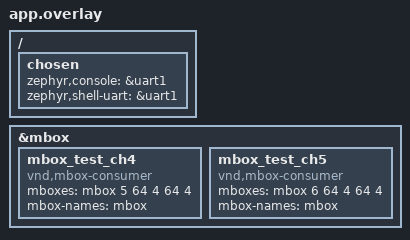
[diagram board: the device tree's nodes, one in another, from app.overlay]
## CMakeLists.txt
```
# SPDX-License-Identifier: Apache-2.0
# mbox_test cpu1 (target) CMakeLists.txt

cmake_minimum_required(VERSION 3.20.0)
find_package(Zephyr REQUIRED HINTS $ENV{ZEPHYR_BASE})
project(cpu1_target_mbox_test)

target_sources(app PRIVATE
    src/main.c
    src/mbox_test_target.c)

target_include_directories(app PRIVATE
    ${CMAKE_CURRENT_SOURCE_DIR}/../tests/include)

include(${CMAKE_CURRENT_SOURCE_DIR}/../../../common/common_sources.cmake)

# 结果上报 + 判定模块（§1.1 修复）：cpu1/cpu2 共用同一份源码
target_sources(app PRIVATE ${CMAKE_CURRENT_SOURCE_DIR}/../tests/src/mbox_test_report.c)

# 扩展 case（P1c 追加）：MBOX_TEST_CASE_ID != 0 时才编入实现文件，
# 保证 case_mbox_basic（ID=0）的构建输入与合并前完全一致。
if(CONFIG_MBOX_TEST_CASE_ID)
    target_sources(app PRIVATE src/mbox_cases.c)
endif()
```

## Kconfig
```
# SPDX-License-Identifier: Apache-2.0
#
# mbox_test cpu1 (target) 应用 Kconfig 根。
# 必须先引入 Zephyr 主配置树，否则整个符号树缺失。

source "$(ZEPHYR_BASE)/Kconfig.zephyr"

# 扩展 case 选择（P1c 追加）。
# 0 = 不编入扩展 case，走原有 mbox_target_main()（case_mbox_basic 原行为）。
config MBOX_TEST_CASE_ID
	int "mbox 扩展 case 编号（0 = 不启用）"
	default 0
	help
	  1 = big_crc   : 4 KB 分片传输 + CRC32 校验
	  2 = stress    : 1000 条往返，丢包/序号/CRC/延迟统计
	  3 = consumers : ch1..ch5 consumer 通路 + 同通道双向
	  4 = invalid   : 异常参数（controller 侧）
	  5 = rtc_sync  : RTC 双核时间同步
	  6 = fifo_full : 屏蔽 IRQ 期 FIFO 满 → -ENOSPC 与补排
```

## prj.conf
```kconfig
CONFIG_LOG=y
CONFIG_LOG_MODE_DEFERRED=y
CONFIG_LOG_BUFFER_SIZE=16384
CONFIG_LOG_PROCESS_THREAD_SLEEP_MS=10
CONFIG_SERIAL=y
CONFIG_SHELL=n
CONFIG_ZTEST=y
CONFIG_ZTEST_ASSERT_VERBOSE=1
CONFIG_ZTEST_VERBOSE_OUTPUT=y
CONFIG_ZTEST_SUMMARY=n
CONFIG_MBOX=y
CONFIG_PICOLIBC=y
CONFIG_NEWLIB_LIBC=n
CONFIG_MINIMAL_LIBC=n
CONFIG_GPIO=y
```

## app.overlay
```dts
/*
 * MBOX test overlay - cpu1 (target) side
 *
 * 新格式（mbox_linkedsemi 驱动改版后）：
 *   mboxes = <&mbox channel tx_width tx_depth rx_width rx_depth>
 *   mbox-names = "mbox"（单一 phandle，不再分 tx/rx）
 *
 * mboxes 首格 = 本节点在 `&mbox` 子节点中的**枚举序**（驱动按遍历序把
 * fifo 填进数组，首格就是数组下标），**以 zephyr.dts 为准**：板级现有 5 个
 * consumer（qspi/otbn/espi/vuart/pcc1 = 0..4），本项目追加 ⇒ 5/6。
 * 节点名 ch4/ch5 为历史命名，实际下标见 mboxes 首格。
 * cpu1 的 tx_fifo_first = <0>（RX fifo first，板级 DTS 已设）。
 */

/ {
	chosen {
		zephyr,console = &uart1;
		zephyr,shell-uart = &uart1;
	};
};

&mbox {
	mbox_test_ch4: mbox_test_ch4 {
		compatible = "vnd,mbox-consumer";
		mboxes = <&mbox 5 64 4 64 4>;
		mbox-names = "mbox";
	};
	mbox_test_ch5: mbox_test_ch5 {
		compatible = "vnd,mbox-consumer";
		mboxes = <&mbox 6 64 4 64 4>;
		mbox-names = "mbox";
	};
};
```

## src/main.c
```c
/*
 * SPDX-License-Identifier: Apache-2.0
 *
 * MBOX test - cpu1 (target) entry point
 * mbox 测试不走 ztest（双核同步复杂），直接跑测试逻辑。
 */

#include <zephyr/kernel.h>
#include <zephyr/logging/log.h>
#include "ztest_glue.h"
#include "mbox_test_report.h"

extern void mbox_target_main(void);
#if defined(CONFIG_MBOX_TEST_CASE_ID) && (CONFIG_MBOX_TEST_CASE_ID > 0)
/* 扩展 case 入口（P1c 追加）：实现见 src/mbox_cases.c，
 * 仅当本目录 Kconfig 的 MBOX_TEST_CASE_ID != 0 时编入。 */
extern void mbox_cases_target_main(void);
#endif

LOG_MODULE_REGISTER(mbox_tgt_main, LOG_LEVEL_INF);

void test_main(void)
{
	LOG_INF("[CPU1 MBOX] MBOX test entry");
	zt_init("TGT");
	mbox_report_init("TGT");

#if defined(CONFIG_MBOX_TEST_CASE_ID) && (CONFIG_MBOX_TEST_CASE_ID > 0)
	mbox_cases_target_main();
#else
	mbox_target_main();
#endif

	/* ★ 按实际判定结果打印 —— 修复前此处**无条件**打 SUCCESSFUL。
	 * 本核的判定状态由 tests/src/mbox_test_report.c 维护（target 侧
	 * 收齐帧数 / payload 校验失败都会置负）。 */
	mbox_print_verdict();

	/* 不返回（§8.1） */
	k_sleep(K_FOREVER);
}
```

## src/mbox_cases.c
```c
/*
 * SPDX-License-Identifier: Apache-2.0
 *
 * MBOX test - cpu1 (target) 扩展 case 实现（P1c 追加）
 *
 * 只实现 V2 协议（mbox_test_protocol.h 追加段）target 侧的应答逻辑；
 * 具体 case 由 CONFIG_MBOX_TEST_CASE_ID 选择（见本目录 Kconfig），
 * 入口 mbox_cases_target_main() 由 src/main.c 在 ID != 0 时调用。
 *
 * 约定：
 *   - ISR 只记账不打 log（§6.1.2），应答统一由本文件的调用线程发送。
 *   - 判定（§1.1/§1.3 修复）：每条 check 用 mbox_item_pass/mbox_item_fail
 *     上报 `INFO <name>: pass=<0|1>,<明细>`，失败置本核判负，src/main.c
 *     在入口返回后按状态打 SUCCESSFUL / FAILED。
 *     修复前失败走 case_fail() 直接打 FAILED，而 main.c 之后仍无条件打
 *     SUCCESSFUL ⇒ 同端口两个互斥标记并存。
 *   - session 判据全在 controller 侧的 case（=4 invalid）用 mbox_item_guard
 *     声明结构性守卫，不得冒充行为证据（§1.4）。
 *   - 驱动的收发 fifo 按通道成对分配于共享 SRAM 的 MBOX 区，同一通道
 *     双向可用，故 echo 类应答走原通道。
 */

#include <zephyr/kernel.h>
#include <zephyr/device.h>
#include <zephyr/devicetree.h>
#include <zephyr/drivers/mbox.h>
#include <zephyr/logging/log.h>
#include <string.h>

#if defined(CONFIG_RTC)
#include <zephyr/drivers/rtc.h>
#endif

#include "mbox_test_protocol.h"
#include "mbox_test_report.h"

LOG_MODULE_REGISTER(mbox_tgt_cases, LOG_LEVEL_INF);

/* consumer 通道 spec。ch0(qspi1) 在本构建中由 flash delegation server
 * 占用（soc_flash_ls.c 注册了回调），扩展 case 不使用该通道。 */
static const struct mbox_dt_spec ch1 = MBOX_DT_SPEC_GET(DT_NODELABEL(mbox_consumer_otbn_crypto), mbox);
static const struct mbox_dt_spec ch2 = MBOX_DT_SPEC_GET(DT_NODELABEL(mbox_consumer_espi1), mbox);
static const struct mbox_dt_spec ch3 = MBOX_DT_SPEC_GET(DT_NODELABEL(mbox_consumer_vuart1), mbox);
static const struct mbox_dt_spec ch4 = MBOX_DT_SPEC_GET(DT_NODELABEL(mbox_test_ch4), mbox);
static const struct mbox_dt_spec ch5 = MBOX_DT_SPEC_GET(DT_NODELABEL(mbox_test_ch5), mbox);

/* 各通道 MTU（= mboxes 的 tx_fifo_width cell，收发同宽） */
#define W_CH1  DT_PHA_BY_IDX(DT_NODELABEL(mbox_consumer_otbn_crypto), mboxes, 0, tx_fifo_width)
#define W_CH2  DT_PHA_BY_IDX(DT_NODELABEL(mbox_consumer_espi1), mboxes, 0, tx_fifo_width)
#define W_CH3  DT_PHA_BY_IDX(DT_NODELABEL(mbox_consumer_vuart1), mboxes, 0, tx_fifo_width)
#define W_CH4  DT_PHA_BY_IDX(DT_NODELABEL(mbox_test_ch4), mboxes, 0, tx_fifo_width)
#define W_CH5  DT_PHA_BY_IDX(DT_NODELABEL(mbox_test_ch5), mboxes, 0, tx_fifo_width)

/* 协议常量必须与板级 dts 一致：FIFO 满 case 的判据依赖 ch4/ch5 深度 */
_Static_assert(MBOX_FIFO_DEPTH ==
	       DT_PHA_BY_IDX(DT_NODELABEL(mbox_test_ch4), mboxes, 0, tx_fifo_depth),
	       "MBOX_FIFO_DEPTH 与 mbox_test_ch4 的 fifo 深度不一致");
_Static_assert(MBOX_TEST_V2_MSG_LEN == W_CH4,
	       "V2 帧长必须等于 ch4 MTU");

/* 暂存槽：驱动侧 rx msg.size 恒为该通道 width，按最大 width（64）开槽 */
#define CASE_RX_SLOT  MBOX_TEST_V2_MSG_LEN

static K_SEM_DEFINE(case_rx_sem, 0, 1);
static uint8_t  case_rx_buf[CASE_RX_SLOT];
static volatile uint32_t case_rx_len;
static volatile uint32_t case_rx_ch;
static volatile uint32_t case_rx_total;
static volatile uint32_t case_rx_drop;

static void case_rx_cb(const struct device *dev, mbox_channel_id_t ch,
		       void *user_data, struct mbox_msg *msg)
{
	/* ISR：只记账 */
	case_rx_total++;
	if (msg == NULL || msg->data == NULL || msg->size > sizeof(case_rx_buf)) {
		case_rx_drop++;
		return;
	}
	memcpy(case_rx_buf, msg->data, msg->size);
	case_rx_len = msg->size;
	case_rx_ch = ch;
	k_sem_give(&case_rx_sem);
}

/* 阻塞等待一条暂存消息；返回 0 = 有消息 */
static int case_wait(uint32_t timeout_ms)
{
	return k_sem_take(&case_rx_sem, K_MSEC(timeout_ms));
}

static void case_take(struct mbox_test_msg_v2 *m)
{
	memset(m, 0, sizeof(*m));
	memcpy(m, case_rx_buf, MIN(case_rx_len, sizeof(*m)));
}

/* 本帧中实际存在的载荷字节数（短通道帧尾部无载荷） */
static uint32_t case_payload_len(void)
{
	return (case_rx_len > MBOX_TEST_V2_HDR_LEN) ?
	       MIN(case_rx_len - MBOX_TEST_V2_HDR_LEN, (uint32_t)MBOX_TEST_V2_DATA_LEN) : 0u;
}

static int case_send(const struct mbox_dt_spec *spec, struct mbox_test_msg_v2 *m, uint32_t size)
{
	struct mbox_msg msg = { .data = m, .size = size };

	return mbox_send_dt(spec, &msg);
}

static void case_setup(const struct mbox_dt_spec *spec)
{
	(void)mbox_register_callback(spec->dev, spec->channel_id, case_rx_cb, NULL);
	(void)mbox_set_enabled(spec->dev, spec->channel_id, true);
}

/* ------------------------------------------------------------------ */
/* case 1：4 KB 分片传输 + CRC32                                        */
/* ------------------------------------------------------------------ */
static void case_big_crc(void)
{
	static uint8_t big[MBOX_BIG_CRC_TOTAL];
	struct mbox_test_msg_v2 m;
	uint32_t got = 0, pattern_err = 0, seq_err = 0, ack_err = 0;
	uint32_t crc_tgt, crc_peer = 0, verdict = MBOX_V2_ST_OK;

	case_setup(&ch4);

	LOG_INF("[TGT] big_crc: expect %u B in %u chunks",
		(unsigned)MBOX_BIG_CRC_TOTAL, (unsigned)MBOX_BIG_CRC_CHUNKS);

	for (;;) {
		if (case_wait(20000) != 0) {
			verdict = MBOX_V2_ST_TIMEOUT;
			break;
		}
		case_take(&m);
		if (m.magic != MBOX_TEST_MAGIC_V2) {
			pattern_err++;
			continue;
		}
		if (m.op == MBOX_V2_OP_DATA) {
			uint32_t off = m.seq * MBOX_TEST_V2_DATA_LEN;
			uint32_t n;
			struct mbox_test_msg_v2 ack;

			if (off >= MBOX_BIG_CRC_TOTAL) {
				seq_err++;
				continue;
			}
			n = MIN((uint32_t)MBOX_TEST_V2_DATA_LEN,
				(uint32_t)MBOX_BIG_CRC_TOTAL - off);
			memcpy(&big[off], m.payload, n);
			for (uint32_t i = 0; i < n; i++) {
				if (big[off + i] != MBOX_BIG_CRC_PATTERN(off + i)) {
					pattern_err++;
				}
			}
			got += n;

			ack.magic = MBOX_TEST_MAGIC_V2;
			ack.op = MBOX_V2_OP_ACK;
			ack.status = (uint8_t)pattern_err;
			ack.seq = m.seq;
			ack.aux = got;
			memset(ack.payload, 0, sizeof(ack.payload));
			if (case_send(&ch5, &ack, W_CH5) != 0) {
				ack_err++;
			}
		} else if (m.op == MBOX_V2_OP_DONE) {
			crc_peer = m.aux;
			break;
		} else {
			pattern_err++;
		}
	}

	crc_tgt = mbox_test_crc32(big, MBOX_BIG_CRC_TOTAL, 0);
	if (got != MBOX_BIG_CRC_TOTAL) {
		verdict = MBOX_V2_ST_SEQ;
	} else if (pattern_err != 0) {
		verdict = MBOX_V2_ST_PATTERN;
	} else if (crc_tgt != crc_peer) {
		verdict = MBOX_V2_ST_CRC;
	}

	/* 汇总上报：aux = 本地 CRC32，payload 前 12 字节 = 接收量/错量 */
	struct mbox_test_msg_v2 stat = {
		.magic = MBOX_TEST_MAGIC_V2,
		.op = MBOX_V2_OP_STAT,
		.status = (uint8_t)verdict,
		.seq = MBOX_BIG_CRC_CHUNKS,
		.aux = crc_tgt,
	};

	memcpy(&stat.payload[0], &got, 4);
	memcpy(&stat.payload[4], &pattern_err, 4);
	memcpy(&stat.payload[8], &ack_err, 4);
	(void)case_send(&ch5, &stat, W_CH5);

	/* ① 端到端完整性：重组字节数 / 逐字节 pattern / 两核 CRC32 */
	if (verdict == MBOX_V2_ST_OK) {
		mbox_item_pass(MBOX_I_BIG_PAYLOAD_CRC, "big_payload_crc",
			       "bytes=%u,recv=%u,pattern_err=%u,seq_err=%u,"
			       "crc=0x%08x,peer_crc=0x%08x",
			       (unsigned)MBOX_BIG_CRC_TOTAL, (unsigned)got,
			       (unsigned)pattern_err, (unsigned)seq_err,
			       (unsigned)crc_tgt, (unsigned)crc_peer);
	} else {
		mbox_item_fail(MBOX_I_BIG_PAYLOAD_CRC, "big_payload_crc",
			       "bytes=%u,recv=%u,pattern_err=%u,seq_err=%u,"
			       "crc=0x%08x,peer_crc=0x%08x,verdict_st=%u",
			       (unsigned)MBOX_BIG_CRC_TOTAL, (unsigned)got,
			       (unsigned)pattern_err, (unsigned)seq_err,
			       (unsigned)crc_tgt, (unsigned)crc_peer,
			       (unsigned)verdict);
	}

	/* ② 逐片 ACK 的回传链路（本核发送侧） */
	if (ack_err == 0 && got == MBOX_BIG_CRC_TOTAL) {
		mbox_item_pass(MBOX_I_BIG_CRC_CHUNK_ACK, "big_crc_chunk_ack",
			       "chunks=%u,ack_err=%u",
			       (unsigned)MBOX_BIG_CRC_CHUNKS, (unsigned)ack_err);
	} else {
		mbox_item_fail(MBOX_I_BIG_CRC_CHUNK_ACK, "big_crc_chunk_ack",
			       "chunks=%u,ack_err=%u,recv=%u",
			       (unsigned)MBOX_BIG_CRC_CHUNKS, (unsigned)ack_err,
			       (unsigned)got);
	}
}

/* ------------------------------------------------------------------ */
/* case 2：1000 条往返，丢包/序号/CRC/延迟统计                          */
/* ------------------------------------------------------------------ */
static void case_stress(void)
{
	struct mbox_test_msg_v2 m;
	uint32_t cnt = 0, seq_err = 0, payload_err = 0, expect = 0;
	uint32_t crc = 0, verdict = MBOX_V2_ST_OK, isr_total, isr_drop;
	bool flow_ok;

	case_setup(&ch4);

	for (;;) {
		if (case_wait(60000) != 0) {
			verdict = MBOX_V2_ST_TIMEOUT;
			break;
		}
		case_take(&m);
		if (m.magic != MBOX_TEST_MAGIC_V2) {
			continue;
		}
		if (m.op == MBOX_V2_OP_DONE) {
			break;
		}
		if (m.op != MBOX_V2_OP_ECHO) {
			continue;
		}

		cnt++;
		if (m.seq != expect) {
			seq_err++;
		}
		expect = m.seq + 1;
		for (uint32_t j = 0; j < MBOX_TEST_V2_DATA_LEN; j++) {
			if (m.payload[j] != (uint8_t)(m.seq + j)) {
				payload_err++;
				break;
			}
		}
		crc = mbox_test_crc32(m.payload, MBOX_TEST_V2_DATA_LEN, crc);

		struct mbox_test_msg_v2 ack = {
			.magic = MBOX_TEST_MAGIC_V2,
			.op = MBOX_V2_OP_ACK,
			.status = (uint8_t)seq_err,
			.seq = m.seq,
			.aux = crc,
		};

		(void)case_send(&ch5, &ack, W_CH5);
	}

	isr_total = case_rx_total;
	isr_drop = case_rx_drop;

	struct mbox_test_msg_v2 stat = {
		.magic = MBOX_TEST_MAGIC_V2,
		.op = MBOX_V2_OP_STAT,
		.status = (uint8_t)((seq_err || payload_err) ? MBOX_V2_ST_SEQ : MBOX_V2_ST_OK),
		.seq = cnt,
		.aux = cnt,
	};

	memcpy(&stat.payload[0], &crc, 4);
	memcpy(&stat.payload[4], &seq_err, 4);
	memcpy(&stat.payload[8], &payload_err, 4);
	memcpy(&stat.payload[12], &isr_total, 4);
	memcpy(&stat.payload[16], &isr_drop, 4);
	(void)case_send(&ch5, &stat, W_CH5);

	flow_ok = (verdict == MBOX_V2_ST_OK) && (seq_err == 0) &&
		  (payload_err == 0) && (isr_drop == 0) &&
		  (cnt == MBOX_STRESS_COUNT);
	if (flow_ok) {
		mbox_item_pass(MBOX_I_STRESS_N_MESSAGES, "stress_n_messages",
			       "recv=%u,expect=%u,seq_err=%u,payload_err=%u,"
			       "isr_total=%u,isr_drop=%u,crc=0x%08x",
			       (unsigned)cnt, (unsigned)MBOX_STRESS_COUNT,
			       (unsigned)seq_err, (unsigned)payload_err,
			       (unsigned)isr_total, (unsigned)isr_drop,
			       (unsigned)crc);
	} else {
		mbox_item_fail(MBOX_I_STRESS_N_MESSAGES, "stress_n_messages",
			       "recv=%u,expect=%u,seq_err=%u,payload_err=%u,"
			       "isr_total=%u,isr_drop=%u,crc=0x%08x,verdict_st=%u",
			       (unsigned)cnt, (unsigned)MBOX_STRESS_COUNT,
			       (unsigned)seq_err, (unsigned)payload_err,
			       (unsigned)isr_total, (unsigned)isr_drop,
			       (unsigned)crc, (unsigned)verdict);
	}
}

/* ------------------------------------------------------------------ */
/* case 3：consumer 通道通路（ch1..ch5；ch0 归 flash delegation）        */
/* ------------------------------------------------------------------ */
static const struct mbox_dt_spec *probe_ch[] = { &ch1, &ch2, &ch3, &ch4 };
static const uint32_t probe_w[] = { W_CH1, W_CH2, W_CH3, W_CH4 };
static const char *probe_name[] = {
	"consumer_ch1_roundtrip", "consumer_ch2_roundtrip",
	"consumer_ch3_roundtrip", "consumer_ch4_roundtrip"
};
static const enum mbox_item probe_item[] = {
	MBOX_I_CONSUMER_CH1, MBOX_I_CONSUMER_CH2, MBOX_I_CONSUMER_CH3, MBOX_I_CONSUMER_CH4
};
#define PROBE_N ARRAY_SIZE(probe_ch)

static void case_consumers(void)
{
	struct mbox_test_msg_v2 m;
	uint32_t ok = 0, bad = 0;
	uint32_t short_frame_len = 0;
	bool probe_ok[PROBE_N];
	bool short_ok;

	for (uint32_t i = 0; i < PROBE_N; i++) {
		case_setup(probe_ch[i]);
		probe_ok[i] = false;
	}
	case_setup(&ch5);

	for (uint32_t i = 0; i < PROBE_N; i++) {
		struct mbox_test_msg_v2 ack;
		bool this_ok = false;
		bool payload_ok = true;

		if (case_wait(5000) != 0) {
			continue;
		}
		case_take(&m);
		if (m.magic == MBOX_TEST_MAGIC_V2 && m.op == MBOX_V2_OP_ECHO &&
		    m.seq == i && case_rx_ch == probe_ch[i]->channel_id &&
		    case_rx_len == probe_w[i]) {
			/* 载荷区只在通道 width > V2 头部长度时存在 */
			for (uint32_t j = 0; j < case_payload_len(); j++) {
				if (m.payload[j] != (uint8_t)(0xA0 + i)) {
					payload_ok = false;
					break;
				}
			}
			this_ok = payload_ok;
		}

		ack.magic = MBOX_TEST_MAGIC_V2;
		ack.op = MBOX_V2_OP_ACK;
		ack.status = this_ok ? MBOX_V2_ST_OK : MBOX_V2_ST_ARG;
		ack.seq = i;
		ack.aux = case_rx_ch;
		memset(ack.payload, 0, sizeof(ack.payload));
		if (case_send(probe_ch[i], &ack, probe_w[i]) == 0 && this_ok) {
			probe_ok[i] = true;
			ok++;
		} else {
			bad++;
		}
	}

	/* ch5 短帧：controller 只发 8 B，驱动 rx size 恒报通道 width(64) */
	if (case_wait(5000) == 0) {
		struct mbox_test_msg_v2 ack;

		case_take(&m);
		short_frame_len = case_rx_len;
		short_ok = (m.op == MBOX_V2_OP_ECHO) && (case_rx_len == W_CH5);
		ack.magic = MBOX_TEST_MAGIC_V2;
		ack.op = MBOX_V2_OP_ACK;
		ack.status = short_ok ? MBOX_V2_ST_OK : MBOX_V2_ST_ARG;
		ack.seq = m.seq;
		ack.aux = case_rx_len;
		memset(ack.payload, 0, sizeof(ack.payload));
		(void)case_send(&ch5, &ack, W_CH5);
	} else {
		short_ok = false;
		bad++;
	}

	/* ① 每个 consumer 通道各自一项 */
	for (uint32_t i = 0; i < PROBE_N; i++) {
		if (probe_ok[i]) {
			mbox_item_pass(probe_item[i], probe_name[i],
				       "ch=%u,size=%u",
				       (unsigned)probe_ch[i]->channel_id,
				       (unsigned)probe_w[i]);
		} else {
			mbox_item_fail(probe_item[i], probe_name[i],
				       "ch=%u,size=%u",
				       (unsigned)probe_ch[i]->channel_id,
				       (unsigned)probe_w[i]);
		}
	}

	/* ② 同一通道双向：ACK 必须由收到的原通道发回（本核 TX/RX region 对偶） */
	if (ok == PROBE_N && bad == 0) {
		mbox_item_pass(MBOX_I_CONSUMER_BIDIR, "consumer_same_channel_bidir",
			       "bidir_ok=%u/%u", (unsigned)ok, (unsigned)PROBE_N);
	} else {
		mbox_item_fail(MBOX_I_CONSUMER_BIDIR, "consumer_same_channel_bidir",
			       "bidir_ok=%u/%u,bad=%u", (unsigned)ok,
			       (unsigned)PROBE_N, (unsigned)bad);
	}

	/* ③ ch5 短帧契约：对端发 8 B，本端 rx size 仍报通道 width(64) */
	if (short_ok) {
		mbox_item_pass(MBOX_I_CONSUMER_CH5_SHORT, "consumer_ch5_short_frame",
			       "rx_len=%u,expect=%u",
			       (unsigned)short_frame_len, (unsigned)W_CH5);
	} else {
		mbox_item_fail(MBOX_I_CONSUMER_CH5_SHORT, "consumer_ch5_short_frame",
			       "rx_len=%u,expect=%u",
			       (unsigned)short_frame_len, (unsigned)W_CH5);
	}
}

/* ------------------------------------------------------------------ */
/* case 4：异常参数（判据在 controller 侧，target 仅待机）               */
/* ------------------------------------------------------------------ */
static void case_invalid(void)
{
	/* 本 case 的判据（非法入参返回值）全部在 controller 侧，target 侧
	 * 没有可校验的行为 —— 用 guard 显式声明"本项不是行为证据"，避免它
	 * 继续冒充"双核行为验证"的一半（§1.4）。 */
	LOG_INF("[TGT] invalid: 判据在 controller 侧，target 待机");
	k_msleep(4000);
	mbox_item_guard(MBOX_I_STRUCT_GUARD, "tgt_invalid_idle", "idle_ms=4000");
}

/* ------------------------------------------------------------------ */
/* case 5：RTC 双核时间同步                                            */
/* ------------------------------------------------------------------ */
static void case_rtc_sync(void)
{
#if defined(CONFIG_RTC)
	const struct device *rtc = DEVICE_DT_GET(DT_NODELABEL(rtc));
	struct rtc_time tm;
	struct mbox_test_msg_v2 m, ack;
	uint32_t e1 = 0, e2 = 0;
	int32_t advance = -1;
	uint32_t bad = 0;

	case_setup(&ch4);

	if (!device_is_ready(rtc)) {
		mbox_mark_fail("rtc device not ready");
		return;
	}

	/* 第 1 轮：应答 controller 的时间戳请求 */
	if (case_wait(20000) != 0) {
		mbox_mark_fail("rtc sync round1 超时");
		return;
	}
	case_take(&m);
	if (rtc_get_time(rtc, &tm) != 0) {
		bad++;
	} else {
		e1 = mbox_test_epoch(tm.tm_year + 1900, tm.tm_mon, tm.tm_mday,
				     tm.tm_hour, tm.tm_min, tm.tm_sec);
	}

	/* 走时推进：隔 300 ms 再读一次，本地 RTC 应前进 0..3 s */
	k_msleep(300);
	if (rtc_get_time(rtc, &tm) != 0) {
		bad++;
	} else {
		e2 = mbox_test_epoch(tm.tm_year + 1900, tm.tm_mon, tm.tm_mday,
				     tm.tm_hour, tm.tm_min, tm.tm_sec);
		advance = (int32_t)e2 - (int32_t)e1;
	}

	memset(&ack, 0, sizeof(ack));
	ack.magic = MBOX_TEST_MAGIC_V2;
	ack.op = MBOX_V2_OP_TS;
	ack.status = (uint8_t)bad;
	ack.seq = m.seq;
	ack.aux = e1;
	memcpy(&ack.payload[0], &advance, 4);
	(void)case_send(&ch5, &ack, W_CH5);

	/* 第 2 轮：供 controller 判单调 */
	if (case_wait(10000) == 0) {
		case_take(&m);
		if (rtc_get_time(rtc, &tm) != 0) {
			bad++;
		} else {
			e2 = mbox_test_epoch(tm.tm_year + 1900, tm.tm_mon, tm.tm_mday,
					     tm.tm_hour, tm.tm_min, tm.tm_sec);
		}
		ack.seq = m.seq;
		ack.aux = e2;
		ack.status = (uint8_t)bad;
		memset(ack.payload, 0, sizeof(ack.payload));
		(void)case_send(&ch5, &ack, W_CH5);
	} else {
		bad++;
	}

	/* RTC 1 Hz 计数：300 ms 内前进量 ∈ [0, 3] s（见 COVERAGE §3.6） */
	if (bad == 0 && advance >= 0 && advance <= 3) {
		mbox_item_pass(MBOX_I_RTC_READ_ADVANCES, "rtc_read_advances",
			       "e1=%u,e2=%u,advance_s=%d,source=local",
			       (unsigned)e1, (unsigned)e2, (int)advance);
	} else {
		mbox_item_fail(MBOX_I_RTC_READ_ADVANCES, "rtc_read_advances",
			       "e1=%u,e2=%u,advance_s=%d,bad=%u,source=local",
			       (unsigned)e1, (unsigned)e2, (int)advance,
			       (unsigned)bad);
	}
#else
	LOG_ERR("[TGT] rtc_sync 需要 CONFIG_RTC=y");
	mbox_mark_fail("CONFIG_RTC 未启用");
#endif
}

/* ------------------------------------------------------------------ */
/* case 6：屏蔽 IRQ 期间 FIFO 满 → -ENOSPC，再使能后补排                */
/* ------------------------------------------------------------------ */
static void case_fifo_full(void)
{
	uint32_t drained;

	case_setup(&ch4);

	/* 屏蔽本核 mbox IRQ：窗口内 ch4 的 RX fifo 不被排空，
	 * controller 的第 depth+1 次发送必然命中驱动的 -ENOSPC 分支。 */
	(void)mbox_set_enabled(ch4.dev, ch4.channel_id, false);
	LOG_INF("[TGT] fifo_full: IRQ masked, waiting controller burst");
	k_msleep(800);

	/* 重新使能：驱动在 set_enabled(true) 内补排已入队消息（回调被唤起） */
	(void)mbox_set_enabled(ch4.dev, ch4.channel_id, true);
	k_msleep(100);

	drained = case_rx_total;

	if (drained == MBOX_FIFO_DEPTH && case_rx_drop == 0) {
		mbox_item_pass(MBOX_I_FIFO_FULL_DRAIN, "fifo_full_drain_on_enable",
			       "drained=%u,drop=%u,expect=%u",
			       (unsigned)drained, (unsigned)case_rx_drop,
			       (unsigned)MBOX_FIFO_DEPTH);
	} else {
		mbox_item_fail(MBOX_I_FIFO_FULL_DRAIN, "fifo_full_drain_on_enable",
			       "drained=%u,drop=%u,expect=%u",
			       (unsigned)drained, (unsigned)case_rx_drop,
			       (unsigned)MBOX_FIFO_DEPTH);
	}
}

/* ------------------------------------------------------------------ */
/* 入口                                                                */
/* ------------------------------------------------------------------ */
void mbox_cases_target_main(void)
{
	LOG_INF("[TGT] extended mbox case id=%d", CONFIG_MBOX_TEST_CASE_ID);

	switch (CONFIG_MBOX_TEST_CASE_ID) {
	case MBOX_CASE_BIG_CRC:
		case_big_crc();
		break;
	case MBOX_CASE_STRESS:
		case_stress();
		break;
	case MBOX_CASE_CONSUMERS:
		case_consumers();
		break;
	case MBOX_CASE_INVALID:
		case_invalid();
		break;
	case MBOX_CASE_RTC_SYNC:
		case_rtc_sync();
		break;
	case MBOX_CASE_FIFO_FULL:
		case_fifo_full();
		break;
	default:
		LOG_ERR("[TGT] unknown case id %d", CONFIG_MBOX_TEST_CASE_ID);
		mbox_mark_fail("unknown MBOX_TEST_CASE_ID");
		break;
	}

	LOG_INF("[TGT] extended case done");
}
```

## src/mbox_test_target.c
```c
/*
 * SPDX-License-Identifier: Apache-2.0
 *
 * MBOX test - cpu1 (target) side
 * 等待 cpu2 发送消息，验证 pattern，回复确认。
 *
 * 驱动改版后用单一 mbox-names="mbox"（不再分 tx/rx）。
 *
 * 判定（§1.1 修复）：修复前本函数**从不校验**收到的内容与条数 —— 只要两个
 * 通道各收到过 ≥1 帧就退出，然后 main.c 无条件打 SUCCESSFUL ⇒ 对端一条都
 * 收不到也判 PASS（等着等着超时同样打 SUCCESS）。现在：
 *   - 每条消息在 ISR 里过 mbox_test_verify()（magic / channel / payload pattern）
 *     与序号连续性检查，只记账不打 log（§6.1.2）；
 *   - 主线程等到**契约条数**（ch4=MBOX_BASIC_CH4_COUNT、ch5=MBOX_BASIC_CH5_COUNT）
 *     或超时才退出，再按 条数 + 校验错 逐项上报。
 */

#include <zephyr/kernel.h>
#include <zephyr/device.h>
#include <zephyr/devicetree.h>
#include <zephyr/drivers/mbox.h>
#include <zephyr/logging/log.h>
#include <string.h>

#include "mbox_test_protocol.h"
#include "mbox_test_report.h"

LOG_MODULE_REGISTER(mbox_tgt, LOG_LEVEL_INF);

/* 单一 mbox spec（新版驱动，mbox-names="mbox"） */
static const struct mbox_dt_spec mbox_ch4 = MBOX_DT_SPEC_GET(DT_NODELABEL(mbox_test_ch4), mbox);
static const struct mbox_dt_spec mbox_ch5 = MBOX_DT_SPEC_GET(DT_NODELABEL(mbox_test_ch5), mbox);

/* 驱动约定：rx 回调上报的 msg.size 恒为该通道 width（mbox_linkedsemi.c:135-138），
 * ch4/ch5 的 width 均为 64，故整帧长度 = sizeof(struct mbox_test_msg)。 */
_Static_assert(sizeof(struct mbox_test_msg) ==
	       DT_PHA_BY_IDX(DT_NODELABEL(mbox_test_ch4), mboxes, 0, rx_fifo_width),
	       "basic 校验要求 ch4 rx width == V1 帧长");

static volatile uint32_t rx_count_ch4;
static volatile uint32_t rx_count_ch5;
static volatile uint32_t verify_err_ch4;
static volatile uint32_t verify_err_ch5;
static volatile uint32_t seq_err_ch4;
static volatile uint32_t seq_err_ch5;
static volatile uint32_t next_seq_ch4;
static volatile uint32_t next_seq_ch5;

static void mbox_rx_callback(const struct device *dev, mbox_channel_id_t channel,
			      void *user_data, struct mbox_msg *msg)
{
	/* ISR: 只记账，不打 log */
	uint32_t ch = (uint32_t)channel;
	bool is_ch4 = (ch == (uint32_t)mbox_ch4.channel_id);
	bool is_ch5 = (ch == (uint32_t)mbox_ch5.channel_id);

	if (!is_ch4 && !is_ch5) {
		return;
	}

	if (msg == NULL || msg->data == NULL ||
	    msg->size < sizeof(struct mbox_test_msg)) {
		/* 短帧/空帧：本工程的基本 case 只发整帧，收到即为驱动异常 */
		if (is_ch4) {
			verify_err_ch4++;
		} else {
			verify_err_ch5++;
		}
		return;
	}

	const struct mbox_test_msg *m = (const struct mbox_test_msg *)msg->data;

	if (mbox_test_verify(m, (uint8_t)ch) != 0) {
		if (is_ch4) {
			verify_err_ch4++;
		} else {
			verify_err_ch5++;
		}
	}

	/* 同一通道的 TX/RX FIFO 是环形队列（peek 取最老项 → drop），
	 * 送达序必与发送序一致，故序号连续性是可断言的驱动不变量。 */
	if (is_ch4) {
		if (m->seq != next_seq_ch4) {
			seq_err_ch4++;
		}
		next_seq_ch4 = m->seq + 1;
		rx_count_ch4++;
	} else {
		if (m->seq != next_seq_ch5) {
			seq_err_ch5++;
		}
		next_seq_ch5 = m->seq + 1;
		rx_count_ch5++;
	}
}

static int send_ack(const struct mbox_dt_spec *spec, uint32_t seq)
{
	struct mbox_test_msg ack = {
		.magic = MBOX_TEST_MAGIC,
		.channel = (uint8_t)spec->channel_id,
		.seq = seq,
	};
	memset(ack.payload, 0xAA, sizeof(ack.payload));
	struct mbox_msg m = { .data = &ack, .size = sizeof(ack) };
	return mbox_send_dt(spec, &m);
}

void mbox_target_main(void)
{
	bool ok4, ok5;

	LOG_INF("[CPU1 MBOX] MBOX target test started");

	(void)mbox_register_callback(mbox_ch4.dev, mbox_ch4.channel_id, mbox_rx_callback, NULL);
	(void)mbox_register_callback(mbox_ch5.dev, mbox_ch5.channel_id, mbox_rx_callback, NULL);
	(void)mbox_set_enabled(mbox_ch4.dev, mbox_ch4.channel_id, 1);
	(void)mbox_set_enabled(mbox_ch5.dev, mbox_ch5.channel_id, 1);

	LOG_INF("[CPU1 MBOX] waiting for cpu2 messages...");

	/* 等到契约条数齐（最多 30s）。修复前判据是"两通道各收到 ≥1 帧"即
	 * break —— 条数少一半也照样退出然后打 SUCCESS。 */
	for (int t = 0; t < 300; t++) {
		if (rx_count_ch4 >= MBOX_BASIC_CH4_COUNT &&
		    rx_count_ch5 >= MBOX_BASIC_CH5_COUNT) {
			break;
		}
		k_msleep(100);
	}

	LOG_INF("[CPU1 MBOX] ch4_rx=%u ch5_rx=%u verify_err=%u/%u seq_err=%u/%u",
		rx_count_ch4, rx_count_ch5, verify_err_ch4, verify_err_ch5,
		seq_err_ch4, seq_err_ch5);

	ok4 = (rx_count_ch4 == MBOX_BASIC_CH4_COUNT) && (verify_err_ch4 == 0) &&
	      (seq_err_ch4 == 0);
	ok5 = (rx_count_ch5 == MBOX_BASIC_CH5_COUNT) && (verify_err_ch5 == 0) &&
	      (seq_err_ch5 == 0);

	/* 逐项上报（判据见 COVERAGE.md §2）。条数不对 / payload pattern 不符 /
	 * 序号断裂 ⇒ 本核判负 ⇒ main.c 打 PROJECT EXECUTION: FAILED。 */
	if (ok4) {
		mbox_item_pass(MBOX_I_BASIC_CH4, "basic_ch4_frames",
			       "recv=%u,expect=%u,verify_err=%u,seq_err=%u",
			       rx_count_ch4, MBOX_BASIC_CH4_COUNT, verify_err_ch4,
			       seq_err_ch4);
	} else {
		mbox_item_fail(MBOX_I_BASIC_CH4, "basic_ch4_frames",
			       "recv=%u,expect=%u,verify_err=%u,seq_err=%u",
			       rx_count_ch4, MBOX_BASIC_CH4_COUNT, verify_err_ch4,
			       seq_err_ch4);
	}

	if (ok5) {
		mbox_item_pass(MBOX_I_BASIC_CH5, "basic_ch5_frames",
			       "recv=%u,expect=%u,verify_err=%u,seq_err=%u",
			       rx_count_ch5, MBOX_BASIC_CH5_COUNT, verify_err_ch5,
			       seq_err_ch5);
	} else {
		mbox_item_fail(MBOX_I_BASIC_CH5, "basic_ch5_frames",
			       "recv=%u,expect=%u,verify_err=%u,seq_err=%u",
			       rx_count_ch5, MBOX_BASIC_CH5_COUNT, verify_err_ch5,
			       seq_err_ch5);
	}

	/* MTU 满帧（TC4）不校验内容：它的判据在 cpu2 侧的返回值。 */

	(void)send_ack(&mbox_ch4, rx_count_ch4);
	(void)send_ack(&mbox_ch5, rx_count_ch5);

	LOG_INF("[CPU1 MBOX] target done");
}
```
